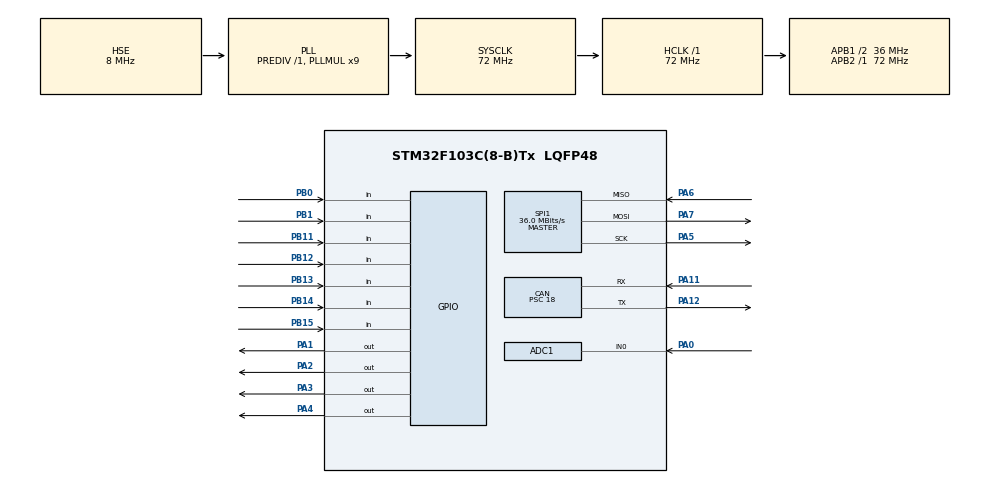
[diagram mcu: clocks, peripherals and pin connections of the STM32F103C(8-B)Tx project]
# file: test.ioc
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ADC1.Channel-0\#ChannelRegularConversion=ADC_CHANNEL_0
ADC1.ContinuousConvMode=ENABLE
ADC1.NbrOfConversionFlag=1
ADC1.Rank-0\#ChannelRegularConversion=1
ADC1.SamplingTime-0\#ChannelRegularConversion=ADC_SAMPLETIME_1CYCLE_5
ADC1.master=1
CAN.ABOM=ENABLE
CAN.BS1=CAN_BS1_6TQ
CAN.CalculateBaudRate=250000
CAN.CalculateTimeBit=4000
CAN.CalculateTimeQuantum=500.0
CAN.NART=ENABLE
CAN.Prescaler=18
Mcu.Family=STM32F1
Mcu.Name=STM32F103C(8-B)Tx
Mcu.Package=LQFP48
NVIC.PriorityGroup=NVIC_PRIORITYGROUP_4
NVIC.TIM2_IRQn=true\:0\:0\:false\:false\:true\:true\:true\:true
PA0-WKUP.Signal=ADCx_IN0
PA1.Signal=GPIO_Output
PA11.Mode=CAN_Activate
PA11.Signal=CAN_RX
PA12.Mode=CAN_Activate
PA12.Signal=CAN_TX
PA13.Mode=Serial_Wire
PA13.Signal=SYS_JTMS-SWDIO
PA14.Mode=Serial_Wire
PA14.Signal=SYS_JTCK-SWCLK
PA2.Signal=GPIO_Output
PA3.Signal=GPIO_Output
PA4.Signal=GPIO_Output
PA5.Mode=Full_Duplex_Master
PA5.Signal=SPI1_SCK
PA6.Mode=Full_Duplex_Master
PA6.Signal=SPI1_MISO
PA7.Mode=Full_Duplex_Master
PA7.Signal=SPI1_MOSI
PB0.GPIO_PuPd=GPIO_PULLUP
PB0.Signal=GPIO_Input
PB1.GPIO_PuPd=GPIO_PULLUP
PB1.Signal=GPIO_Input
PB11.GPIO_PuPd=GPIO_PULLUP
PB11.Signal=GPIO_Input
PB12.GPIO_PuPd=GPIO_PULLUP
PB12.Signal=GPIO_Input
PB13.GPIO_PuPd=GPIO_PULLUP
PB13.Signal=GPIO_Input
PB14.GPIO_PuPd=GPIO_PULLUP
PB14.Signal=GPIO_Input
PB15.GPIO_PuPd=GPIO_PULLUP
PB15.Signal=GPIO_Input
PD0-OSC_IN.Mode=HSE-External-Oscillator
PD0-OSC_IN.Signal=RCC_OSC_IN
PD1-OSC_OUT.Mode=HSE-External-Oscillator
PD1-OSC_OUT.Signal=RCC_OSC_OUT
ProjectManager.HeapSize=0x200
ProjectManager.StackSize=0x400
ProjectManager.TargetToolchain=STM32CubeIDE
RCC.ADCPresc=RCC_ADCPCLK2_DIV8
RCC.AHBFreq_Value=72000000
RCC.APB1CLKDivider=RCC_HCLK_DIV2
RCC.APB1Freq_Value=36000000
RCC.APB1TimFreq_Value=72000000
RCC.APB2Freq_Value=72000000
RCC.APB2TimFreq_Value=72000000
RCC.HCLKFreq_Value=72000000
RCC.PLLMUL=RCC_PLL_MUL9
RCC.PLLSourceVirtual=RCC_PLLSOURCE_HSE
RCC.SYSCLKFreq_VALUE=72000000
RCC.SYSCLKSource=RCC_SYSCLKSOURCE_PLLCLK
RCC.USBFreq_Value=72000000
SH.ADCx_IN0.0=ADC1_IN0,IN0
SPI1.BaudRatePrescaler=SPI_BAUDRATEPRESCALER_2
SPI1.CalculateBaudRate=36.0 MBits/s
SPI1.Direction=SPI_DIRECTION_2LINES
SPI1.Mode=SPI_MODE_MASTER
SPI1.VirtualType=VM_MASTER
TIM2.Period=999
TIM2.Prescaler=7199
VP_TIM2_VS_ClockSourceINT.Mode=Internal
board=custom

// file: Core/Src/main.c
/* USER CODE BEGIN Header */
/**
 ******************************************************************************
 * @file           : main.c
 * @brief          : Main program body
 ******************************************************************************
 * @attention
 *
 * Copyright (c) 2026 STMicroelectronics.
 * All rights reserved.
 *
 * This software is licensed under terms that can be found in the LICENSE file
 * in the root directory of this software component.
 * If no LICENSE file comes with this software, it is provided AS-IS.
 *
 ******************************************************************************
 */
/* USER CODE END Header */
#include "main.h"

ADC_HandleTypeDef hadc1;

CAN_HandleTypeDef hcan;

SPI_HandleTypeDef hspi1;

TIM_HandleTypeDef htim2;

void SystemClock_Config(void);
static void MX_GPIO_Init(void);
static void MX_CAN_Init(void);
static void MX_ADC1_Init(void);
static void MX_SPI1_Init(void);
static void MX_TIM2_Init(void);

int main(void)
{

  /* MCU Configuration--------------------------------------------------------*/

  /* Reset of all peripherals, Initializes the Flash interface and the Systick. */
  HAL_Init();

  /* Configure the system clock */
  SystemClock_Config();

  /* Initialize all configured peripherals */
  MX_GPIO_Init();
  MX_CAN_Init();
  MX_ADC1_Init();
  MX_SPI1_Init();
  MX_TIM2_Init();
  /* USER CODE BEGIN 2 */
	App_Init();

  /* USER CODE END 2 */

  /* Infinite loop */
	while (1) {

    /* USER CODE BEGIN 3 */
		App_Run();
	}
  /* USER CODE END 3 */
}

void SystemClock_Config(void)
{
  RCC_OscInitTypeDef RCC_OscInitStruct = {0};
  RCC_ClkInitTypeDef RCC_ClkInitStruct = {0};
  RCC_PeriphCLKInitTypeDef PeriphClkInit = {0};

  /** Initializes the RCC Oscillators according to the specified parameters
  * in the RCC_OscInitTypeDef structure.
  */
  RCC_OscInitStruct.OscillatorType = RCC_OSCILLATORTYPE_HSE;
  RCC_OscInitStruct.HSEState = RCC_HSE_ON;
  RCC_OscInitStruct.HSEPredivValue = RCC_HSE_PREDIV_DIV1;
  RCC_OscInitStruct.HSIState = RCC_HSI_ON;
  RCC_OscInitStruct.PLL.PLLState = RCC_PLL_ON;
  RCC_OscInitStruct.PLL.PLLSource = RCC_PLLSOURCE_HSE;
  RCC_OscInitStruct.PLL.PLLMUL = RCC_PLL_MUL9;
  if (HAL_RCC_OscConfig(&RCC_OscInitStruct) != HAL_OK)
  {
    Error_Handler();
  }

  /** Initializes the CPU, AHB and APB buses clocks
  */
  RCC_ClkInitStruct.ClockType = RCC_CLOCKTYPE_HCLK|RCC_CLOCKTYPE_SYSCLK
                              |RCC_CLOCKTYPE_PCLK1|RCC_CLOCKTYPE_PCLK2;
  RCC_ClkInitStruct.SYSCLKSource = RCC_SYSCLKSOURCE_PLLCLK;
  RCC_ClkInitStruct.AHBCLKDivider = RCC_SYSCLK_DIV1;
  RCC_ClkInitStruct.APB1CLKDivider = RCC_HCLK_DIV2;
  RCC_ClkInitStruct.APB2CLKDivider = RCC_HCLK_DIV1;

  if (HAL_RCC_ClockConfig(&RCC_ClkInitStruct, FLASH_LATENCY_2) != HAL_OK)
  {
    Error_Handler();
  }
  PeriphClkInit.PeriphClockSelection = RCC_PERIPHCLK_ADC;
  PeriphClkInit.AdcClockSelection = RCC_ADCPCLK2_DIV8;
  if (HAL_RCCEx_PeriphCLKConfig(&PeriphClkInit) != HAL_OK)
  {
    Error_Handler();
  }
}

static void MX_ADC1_Init(void)
{

  ADC_ChannelConfTypeDef sConfig = {0};

  /** Common config
  */
  hadc1.Instance = ADC1;
  hadc1.Init.ScanConvMode = ADC_SCAN_DISABLE;
  hadc1.Init.ContinuousConvMode = ENABLE;
  hadc1.Init.DiscontinuousConvMode = DISABLE;
  hadc1.Init.ExternalTrigConv = ADC_SOFTWARE_START;
  hadc1.Init.DataAlign = ADC_DATAALIGN_RIGHT;
  hadc1.Init.NbrOfConversion = 1;
  if (HAL_ADC_Init(&hadc1) != HAL_OK)
  {
    Error_Handler();
  }

  /** Configure Regular Channel
  */
  sConfig.Channel = ADC_CHANNEL_0;
  sConfig.Rank = ADC_REGULAR_RANK_1;
  sConfig.SamplingTime = ADC_SAMPLETIME_1CYCLE_5;
  if (HAL_ADC_ConfigChannel(&hadc1, &sConfig) != HAL_OK)
  {
    Error_Handler();
  }

}

static void MX_CAN_Init(void)
{

  hcan.Instance = CAN1;
  hcan.Init.Prescaler = 18;
  hcan.Init.Mode = CAN_MODE_NORMAL;
  hcan.Init.SyncJumpWidth = CAN_SJW_1TQ;
  hcan.Init.TimeSeg1 = CAN_BS1_6TQ;
  hcan.Init.TimeSeg2 = CAN_BS2_1TQ;
  hcan.Init.TimeTriggeredMode = DISABLE;
  hcan.Init.AutoBusOff = ENABLE;
  hcan.Init.AutoWakeUp = DISABLE;
  hcan.Init.AutoRetransmission = ENABLE;
  hcan.Init.ReceiveFifoLocked = DISABLE;
  hcan.Init.TransmitFifoPriority = DISABLE;
  if (HAL_CAN_Init(&hcan) != HAL_OK)
  {
    Error_Handler();
  }

}

static void MX_SPI1_Init(void)
{

  /* SPI1 parameter configuration*/
  hspi1.Instance = SPI1;
  hspi1.Init.Mode = SPI_MODE_MASTER;
  hspi1.Init.Direction = SPI_DIRECTION_2LINES;
  hspi1.Init.DataSize = SPI_DATASIZE_8BIT;
  hspi1.Init.CLKPolarity = SPI_POLARITY_LOW;
  hspi1.Init.CLKPhase = SPI_PHASE_1EDGE;
  hspi1.Init.NSS = SPI_NSS_SOFT;
  hspi1.Init.BaudRatePrescaler = SPI_BAUDRATEPRESCALER_2;
  hspi1.Init.FirstBit = SPI_FIRSTBIT_MSB;
  hspi1.Init.TIMode = SPI_TIMODE_DISABLE;
  hspi1.Init.CRCCalculation = SPI_CRCCALCULATION_DISABLE;
  hspi1.Init.CRCPolynomial = 10;
  if (HAL_SPI_Init(&hspi1) != HAL_OK)
  {
    Error_Handler();
  }

}

static void MX_TIM2_Init(void)
{

  TIM_ClockConfigTypeDef sClockSourceConfig = {0};
  TIM_MasterConfigTypeDef sMasterConfig = {0};

  htim2.Instance = TIM2;
  htim2.Init.Prescaler = 7199;
  htim2.Init.CounterMode = TIM_COUNTERMODE_UP;
  htim2.Init.Period = 999;
  htim2.Init.ClockDivision = TIM_CLOCKDIVISION_DIV1;
  htim2.Init.AutoReloadPreload = TIM_AUTORELOAD_PRELOAD_DISABLE;
  if (HAL_TIM_Base_Init(&htim2) != HAL_OK)
  {
    Error_Handler();
  }
  sClockSourceConfig.ClockSource = TIM_CLOCKSOURCE_INTERNAL;
  if (HAL_TIM_ConfigClockSource(&htim2, &sClockSourceConfig) != HAL_OK)
  {
    Error_Handler();
  }
  sMasterConfig.MasterOutputTrigger = TIM_TRGO_RESET;
  sMasterConfig.MasterSlaveMode = TIM_MASTERSLAVEMODE_DISABLE;
  if (HAL_TIMEx_MasterConfigSynchronization(&htim2, &sMasterConfig) != HAL_OK)
  {
    Error_Handler();
  }

}

static void MX_GPIO_Init(void)
{
  GPIO_InitTypeDef GPIO_InitStruct = {0};

  /* GPIO Ports Clock Enable */
  __HAL_RCC_GPIOD_CLK_ENABLE();
  __HAL_RCC_GPIOA_CLK_ENABLE();
  __HAL_RCC_GPIOB_CLK_ENABLE();

  /*Configure GPIO pin Output Level */
  HAL_GPIO_WritePin(GPIOA, GPIO_PIN_1|GPIO_PIN_2|GPIO_PIN_3|GPIO_PIN_4, GPIO_PIN_RESET);

  /*Configure GPIO pins : PA1 PA2 PA3 PA4 */
  GPIO_InitStruct.Pin = GPIO_PIN_1|GPIO_PIN_2|GPIO_PIN_3|GPIO_PIN_4;
  GPIO_InitStruct.Mode = GPIO_MODE_OUTPUT_PP;
  GPIO_InitStruct.Pull = GPIO_NOPULL;
  GPIO_InitStruct.Speed = GPIO_SPEED_FREQ_LOW;
  HAL_GPIO_Init(GPIOA, &GPIO_InitStruct);

  /*Configure GPIO pins : PB0 PB1 PB11 PB12
                           PB13 PB14 PB15 */
  GPIO_InitStruct.Pin = GPIO_PIN_0|GPIO_PIN_1|GPIO_PIN_11|GPIO_PIN_12
                          |GPIO_PIN_13|GPIO_PIN_14|GPIO_PIN_15;
  GPIO_InitStruct.Mode = GPIO_MODE_INPUT;
  GPIO_InitStruct.Pull = GPIO_PULLUP;
  HAL_GPIO_Init(GPIOB, &GPIO_InitStruct);

}

void Error_Handler(void)
{
	__disable_irq();
	while (1) {
	}
}
